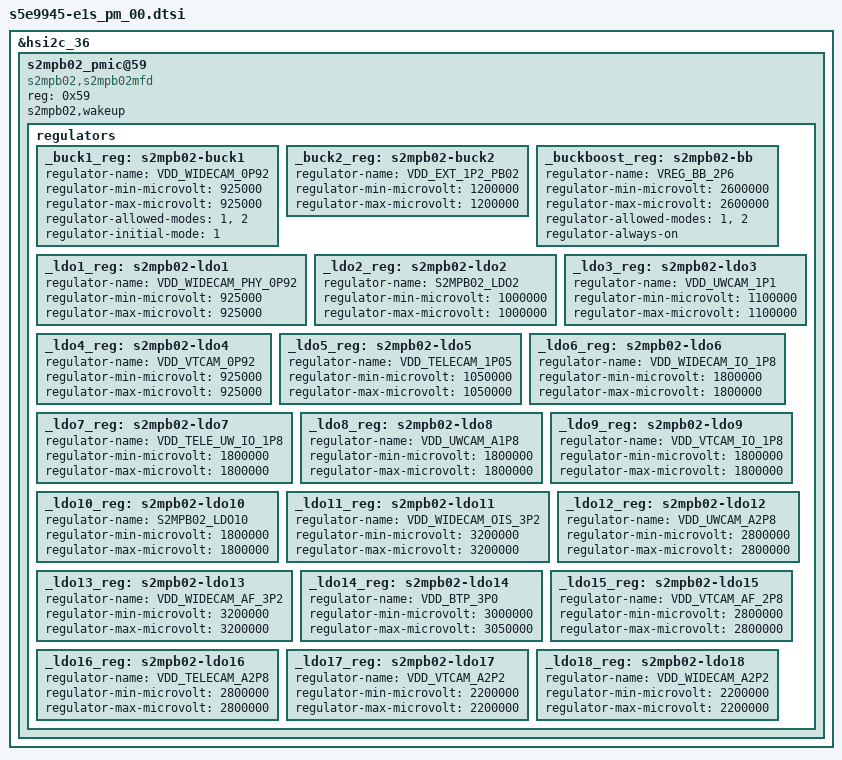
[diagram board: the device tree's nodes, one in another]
/*
 * SAMSUNG S5E9945 Display, Camera PMIC device tree source
 *
 * Copyright (c) 2023 Samsung Electronics Co., Ltd.
 *             http://www.samsung.com
 *
 * SAMSUNG S5E9945 Display, Camera PMIC device nodes are listed in this file.
 * EXYNOS based board files can include this file and provide
 * values for board specfic bindings.
 *
 * This program is free software; you can redistribute it and/or modify
 * it under the terms of the GNU General Public License version 2 as
 * published by the Free Software Foundation.
 */

#include "../s5e9945-sec_pm_common.dtsi"
#include "s5e9945-e1s_pm_thermistor.dtsi"

&hsi2c_36 {
	#address-cells = <1>;
	#size-cells = <0>;
	status = "okay";
	s2mpb02_pmic@59 {
		compatible = "s2mpb02,s2mpb02mfd";
		reg = <0x59>;

		s2mpb02,wakeup;

		regulators {
			_buck1_reg: s2mpb02-buck1 {
				regulator-name = "VDD_WIDECAM_0P92";
				regulator-min-microvolt = <925000>;
				regulator-max-microvolt = <925000>;
				regulator-allowed-modes = <1>, <2>;
				regulator-initial-mode = <1>;
			};

			_buck2_reg: s2mpb02-buck2 {
				regulator-name = "VDD_EXT_1P2_PB02";
				regulator-min-microvolt = <1200000>;
				regulator-max-microvolt = <1200000>;
			};

			_buckboost_reg: s2mpb02-bb {
				regulator-name = "VREG_BB_2P6";
				regulator-min-microvolt = <2600000>;
				regulator-max-microvolt = <2600000>;
				regulator-allowed-modes = <1>, <2>;
				regulator-always-on;
			};

			_ldo1_reg: s2mpb02-ldo1 {
				regulator-name = "VDD_WIDECAM_PHY_0P92";
				regulator-min-microvolt = <925000>;
				regulator-max-microvolt = <925000>;
			};

			_ldo2_reg: s2mpb02-ldo2 {
				regulator-name = "S2MPB02_LDO2";
				regulator-min-microvolt = <1000000>;
				regulator-max-microvolt = <1000000>;
			};

			_ldo3_reg: s2mpb02-ldo3 {
				regulator-name = "VDD_UWCAM_1P1";
				regulator-min-microvolt = <1100000>;
				regulator-max-microvolt = <1100000>;
			};

			_ldo4_reg: s2mpb02-ldo4 {
				regulator-name = "VDD_VTCAM_0P92";
				regulator-min-microvolt = <925000>;
				regulator-max-microvolt = <925000>;
			};

			_ldo5_reg: s2mpb02-ldo5 {
				regulator-name = "VDD_TELECAM_1P05";
				regulator-min-microvolt = <1050000>;
				regulator-max-microvolt = <1050000>;
			};

			_ldo6_reg: s2mpb02-ldo6 {
				regulator-name = "VDD_WIDECAM_IO_1P8";
				regulator-min-microvolt = <1800000>;
				regulator-max-microvolt = <1800000>;
			};

			_ldo7_reg: s2mpb02-ldo7 {
				regulator-name = "VDD_TELE_UW_IO_1P8";
				regulator-min-microvolt = <1800000>;
				regulator-max-microvolt = <1800000>;
			};

			_ldo8_reg: s2mpb02-ldo8 {
				regulator-name = "VDD_UWCAM_A1P8";
				regulator-min-microvolt = <1800000>;
				regulator-max-microvolt = <1800000>;
			};

			_ldo9_reg: s2mpb02-ldo9 {
				regulator-name = "VDD_VTCAM_IO_1P8";
				regulator-min-microvolt = <1800000>;
				regulator-max-microvolt = <1800000>;
			};

			_ldo10_reg: s2mpb02-ldo10 {
				regulator-name = "S2MPB02_LDO10";
				regulator-min-microvolt = <1800000>;
				regulator-max-microvolt = <1800000>;
			};

			_ldo11_reg: s2mpb02-ldo11 {
				regulator-name = "VDD_WIDECAM_OIS_3P2";
				regulator-min-microvolt = <3200000>;
				regulator-max-microvolt = <3200000>;
			};

			_ldo12_reg: s2mpb02-ldo12 {
				regulator-name = "VDD_UWCAM_A2P8";
				regulator-min-microvolt = <2800000>;
				regulator-max-microvolt = <2800000>;
			};

			_ldo13_reg: s2mpb02-ldo13 {
				regulator-name = "VDD_WIDECAM_AF_3P2";
				regulator-min-microvolt = <3200000>;
				regulator-max-microvolt = <3200000>;
			};

			_ldo14_reg: s2mpb02-ldo14 {
				regulator-name = "VDD_BTP_3P0";
				regulator-min-microvolt = <3000000>;
				regulator-max-microvolt = <3050000>;
			};

			_ldo15_reg: s2mpb02-ldo15 {
				regulator-name = "VDD_VTCAM_AF_2P8";
				regulator-min-microvolt = <2800000>;
				regulator-max-microvolt = <2800000>;
			};

			_ldo16_reg: s2mpb02-ldo16 {
				regulator-name = "VDD_TELECAM_A2P8";
				regulator-min-microvolt = <2800000>;
				regulator-max-microvolt = <2800000>;
			};

			_ldo17_reg: s2mpb02-ldo17 {
				regulator-name = "VDD_VTCAM_A2P2";
				regulator-min-microvolt = <2200000>;
				regulator-max-microvolt = <2200000>;
			};

			_ldo18_reg: s2mpb02-ldo18 {
				regulator-name = "VDD_WIDECAM_A2P2";
				regulator-min-microvolt = <2200000>;
				regulator-max-microvolt = <2200000>;
			};
		};
	};
};
